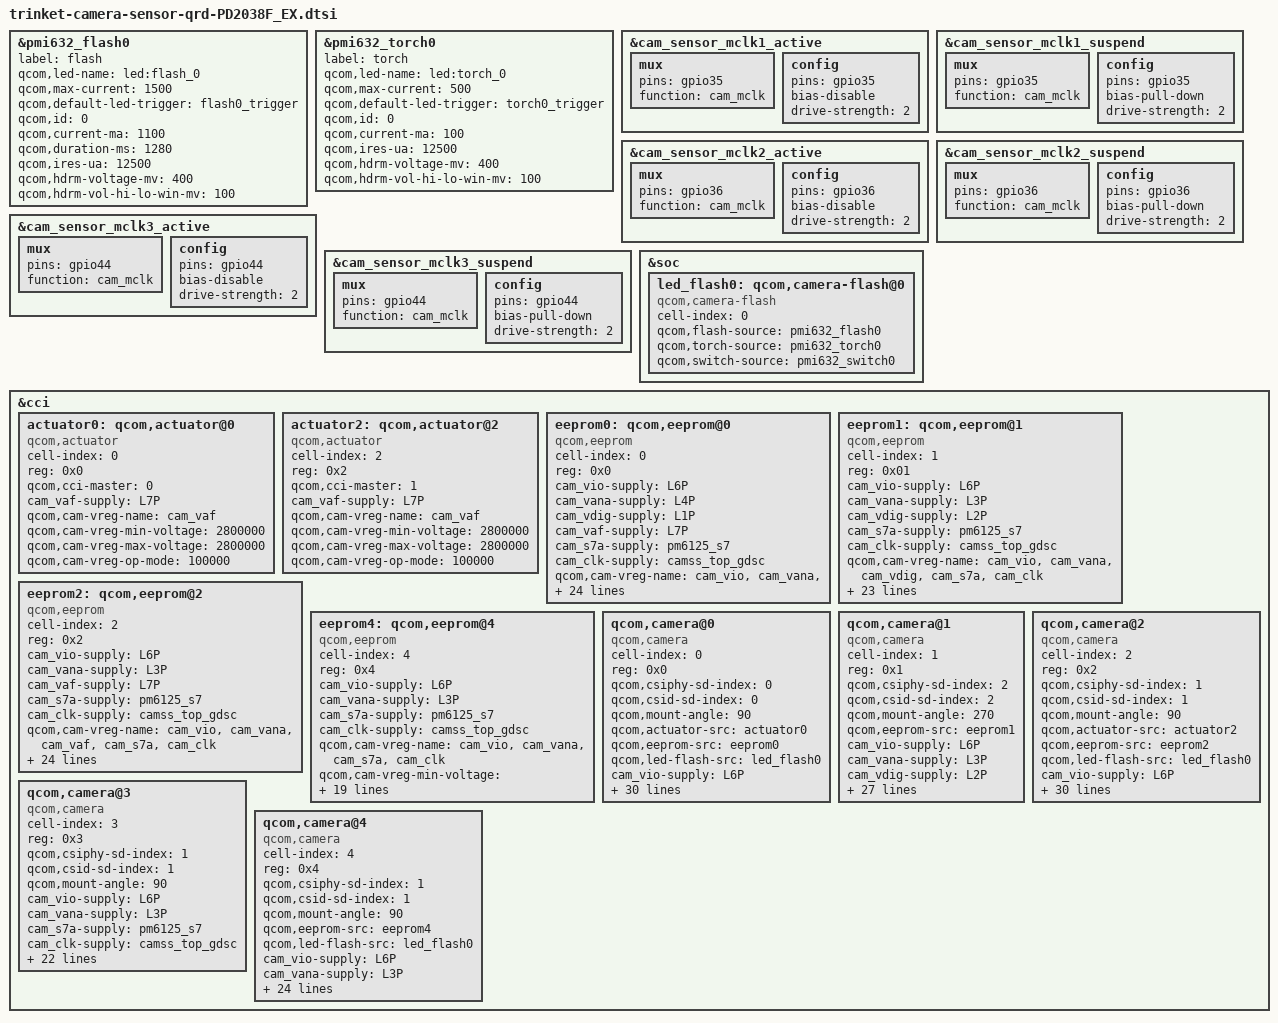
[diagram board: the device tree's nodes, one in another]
/*
 * Copyright (c) 2019, The Linux Foundation. All rights reserved.
 *
 * This program is free software; you can redistribute it and/or modify
 * it under the terms of the GNU General Public License version 2 and
 * only version 2 as published by the Free Software Foundation.
 *
 * This program is distributed in the hope that it will be useful,
 * but WITHOUT ANY WARRANTY; without even the implied warranty of
 * MERCHANTABILITY or FITNESS FOR A PARTICULAR PURPOSE.  See the
 * GNU General Public License for more details.
 */

&pmi632_flash0 {
	label = "flash";
	qcom,led-name = "led:flash_0";
	qcom,max-current = <1500>;
	qcom,default-led-trigger = "flash0_trigger";
	qcom,id = <0>;
	qcom,current-ma = <1100>;
	qcom,duration-ms = <1280>;
	qcom,ires-ua = <12500>;
	qcom,hdrm-voltage-mv = <400>;
	qcom,hdrm-vol-hi-lo-win-mv = <100>;
};

&pmi632_torch0 {
	label = "torch";
	qcom,led-name = "led:torch_0";
	qcom,max-current = <500>;
	qcom,default-led-trigger = "torch0_trigger";
	qcom,id = <0>;
	qcom,current-ma = <100>;
	qcom,ires-ua = <12500>;
	qcom,hdrm-voltage-mv = <400>;
	qcom,hdrm-vol-hi-lo-win-mv = <100>;
};

&cam_sensor_mclk1_active {
	/* MCLK2 */
	mux {
		pins = "gpio35";
		function = "cam_mclk";
	};

	config {
		pins = "gpio35";
		bias-disable; /* No PULL */
		drive-strength = <2>; /* 2 MA */
	};
};

&cam_sensor_mclk1_suspend {
	/* MCLK2 */
	mux {
		pins = "gpio35";
		function = "cam_mclk";
	};

	config {
		pins = "gpio35";
		bias-pull-down; /* PULL DOWN */
		drive-strength = <2>; /* 2 MA */
	};
};

&cam_sensor_mclk2_active {
	/* MCLK2 */
	mux {
		pins = "gpio36";
		function = "cam_mclk";
	};

	config {
		pins = "gpio36";
		bias-disable; /* No PULL */
		drive-strength = <2>; /* 2 MA */
	};
};

&cam_sensor_mclk2_suspend {
	/* MCLK2 */
	mux {
		pins = "gpio36";
		function = "cam_mclk";
	};

	config {
		pins = "gpio36";
		bias-pull-down; /* PULL DOWN */
		drive-strength = <2>; /* 2 MA */
	};
};

&cam_sensor_mclk3_active {
	/* MCLK3 */
	mux {
		pins = "gpio44";
		function = "cam_mclk";
	};

	config {
		pins = "gpio44";
		bias-disable; /* No PULL */
		drive-strength = <2>; /* 2 MA */
	};
};

&cam_sensor_mclk3_suspend {
	/* MCLK2 */
	mux {
		pins = "gpio44";
		function = "cam_mclk";
	};

	config {
		pins = "gpio44";
		bias-pull-down; /* PULL DOWN */
		drive-strength = <2>; /* 2 MA */
	};
};

&soc {
	led_flash0: qcom,camera-flash@0 {
		cell-index = <0>;
		compatible = "qcom,camera-flash";
		qcom,flash-source = <&pmi632_flash0>;
		qcom,torch-source = <&pmi632_torch0>;
		qcom,switch-source = <&pmi632_switch0>;
		status = "ok";
	};
};

&cci {
	actuator0: qcom,actuator@0 {
		cell-index = <0>;
		reg = <0x0>;
		compatible = "qcom,actuator";
		qcom,cci-master = <0>;
		cam_vaf-supply = <&L7P>;
		qcom,cam-vreg-name = "cam_vaf";
		qcom,cam-vreg-min-voltage = <2800000>;
		qcom,cam-vreg-max-voltage = <2800000>;
		qcom,cam-vreg-op-mode = <100000>;
	};

	actuator2: qcom,actuator@2 {
		cell-index = <2>;
		reg = <0x2>;
		compatible = "qcom,actuator";
		qcom,cci-master = <1>;
		cam_vaf-supply = <&L7P>;
		qcom,cam-vreg-name = "cam_vaf";
		qcom,cam-vreg-min-voltage = <2800000>;
		qcom,cam-vreg-max-voltage = <2800000>;
		qcom,cam-vreg-op-mode = <100000>;
	};

	eeprom0: qcom,eeprom@0 {
		cell-index = <0>;
		compatible = "qcom,eeprom";
		reg = <0x0>;
		cam_vio-supply = <&L6P>;
		cam_vana-supply = <&L4P>;
		cam_vdig-supply = <&L1P>;
		cam_vaf-supply = <&L7P>;
		cam_s7a-supply = <&pm6125_s7>;
		cam_clk-supply = <&camss_top_gdsc>;
		qcom,cam-vreg-name = "cam_vio", "cam_vana", "cam_vdig", "cam_vaf", "cam_s7a",  "cam_clk";
		qcom,cam-vreg-min-voltage = <1800000 2800000 1100000 2800000 2040000 0>;
		qcom,cam-vreg-max-voltage = <1800000 2800000 1100000 2800000 2040000 0>;
		qcom,cam-vreg-op-mode = <100000 100000 100000 100000 0 0>;
		qcom,gpio-no-mux = <0>;
		pinctrl-names = "cam_default", "cam_suspend";
		pinctrl-0 = <&cam_sensor_mclk1_active
				&cam_sensor_rear_active>;
		pinctrl-1 = <&cam_sensor_mclk1_suspend
				&cam_sensor_rear_suspend>;
		gpios = <&tlmm 35 0>, <&tlmm 48 0>;
		qcom,gpio-reset = <1>;
		qcom,gpio-req-tbl-num = <0 1>;
		qcom,gpio-req-tbl-flags = <1 0>;
		qcom,gpio-req-tbl-label = "CAMIF_MCLK0", "CAM_RESET0";
		qcom,sensor-position = <0>;
		qcom,sensor-mode = <0>;
		qcom,cci-master = <0>;
		status = "ok";
		clocks = <&clock_gcc GCC_CAMSS_MCLK1_CLK_SRC>,
				<&clock_gcc GCC_CAMSS_MCLK1_CLK>;
		clock-names = "cam_src_clk", "cam_clk";
		qcom,clock-rates = <24000000 0>;
	};

	eeprom1: qcom,eeprom@1 {
		cell-index = <1>;
		reg = <0x01>;
		compatible = "qcom,eeprom";
		cam_vio-supply = <&L6P>;
		cam_vana-supply = <&L3P>;
		cam_vdig-supply = <&L2P>;
		cam_s7a-supply = <&pm6125_s7>;
		cam_clk-supply = <&camss_top_gdsc>;
		qcom,cam-vreg-name = "cam_vio", "cam_vana", "cam_vdig", "cam_s7a", "cam_clk";
		qcom,cam-vreg-min-voltage = <1800000 2800000 1140000 2040000 0>;
		qcom,cam-vreg-max-voltage = <1800000 2800000 1140000 2040000 0>;
		qcom,cam-vreg-op-mode = <100000 100000 100000 0 0>;
		qcom,gpio-no-mux = <0>;
		pinctrl-names = "cam_default", "cam_suspend";
		pinctrl-0 = <&cam_sensor_mclk0_active
				 &cam_sensor_front_active>;
		pinctrl-1 = <&cam_sensor_mclk0_suspend
				 &cam_sensor_front_suspend>;
		gpios = <&tlmm 34 0>, <&tlmm 42 0>;
		qcom,gpio-reset = <1>;
		qcom,gpio-req-tbl-num = <0 1>;
		qcom,gpio-req-tbl-flags = <1 0>;
		qcom,gpio-req-tbl-label = "CAMIF_MCLK1", "CAM_RESET1";
		qcom,sensor-position = <1>;
		qcom,sensor-mode = <1>;
		qcom,cci-master = <0>;
		status = "ok";
		clocks = <&clock_gcc GCC_CAMSS_MCLK0_CLK_SRC>,
			<&clock_gcc GCC_CAMSS_MCLK0_CLK>;
		clock-names = "cam_src_clk", "cam_clk";
		qcom,clock-rates = <24000000 0>;
	};

	eeprom2: qcom,eeprom@2 {
		cell-index = <2>;
		reg = <0x2>;
		compatible = "qcom,eeprom";
		cam_vio-supply = <&L6P>;
		cam_vana-supply = <&L3P>;
		cam_vaf-supply = <&L7P>;
		cam_s7a-supply = <&pm6125_s7>;
		cam_clk-supply = <&camss_top_gdsc>;
		qcom,cam-vreg-name = "cam_vio", "cam_vana", "cam_vaf", "cam_s7a", "cam_clk";
		qcom,cam-vreg-min-voltage = <1800000 2800000 2800000 2040000 0>;
		qcom,cam-vreg-max-voltage = <1800000 2800000 2800000 2040000 0>;
		qcom,cam-vreg-op-mode = <100000 100000 100000 0 0>;
		qcom,gpio-no-mux = <0>;
		pinctrl-names = "cam_default", "cam_suspend";
		pinctrl-0 = <&cam_sensor_mclk2_active
				&cam_sensor_rear3_active>;
		pinctrl-1 = <&cam_sensor_mclk2_suspend
				&cam_sensor_rear3_suspend>;
		gpios = <&tlmm 36 0>, <&tlmm 20 0>, <&tlmm 41 0>;
		qcom,gpio-vdig = <1>;
		qcom,gpio-reset = <2>;
		qcom,gpio-req-tbl-num = <0 1 2>;
		qcom,gpio-req-tbl-flags = <1 0 0>;
		qcom,gpio-req-tbl-label = "CAMIF_MCLK2", "CAM_DVDD2", "CAM_RESET2";
		qcom,sensor-position = <0>;
		qcom,sensor-mode = <0>;
		qcom,cci-master = <1>;
		status = "ok";
		clocks = <&clock_gcc GCC_CAMSS_MCLK2_CLK_SRC>,
				<&clock_gcc GCC_CAMSS_MCLK2_CLK>;
		clock-names = "cam_src_clk", "cam_clk";
		qcom,clock-rates = <24000000 0>;
	};

	eeprom4: qcom,eeprom@4 {
		cell-index = <4>;
		reg = <0x4>;
		compatible = "qcom,eeprom";
		cam_vio-supply = <&L6P>;
		cam_vana-supply = <&L3P>;
		cam_s7a-supply = <&pm6125_s7>;
		cam_clk-supply = <&camss_top_gdsc>;
		qcom,cam-vreg-name = "cam_vio", "cam_vana", "cam_s7a", "cam_clk";
		qcom,cam-vreg-min-voltage = <1800000 2800000 2040000 0>;
		qcom,cam-vreg-max-voltage = <1800000 2800000 2040000 0>;
		qcom,cam-vreg-op-mode = <100000 100000 0 0>;
		qcom,gpio-no-mux = <0>;
		pinctrl-names = "cam_default", "cam_suspend";
		pinctrl-0 = <&cam_sensor_mclk2_active>;
		pinctrl-1 = <&cam_sensor_mclk2_suspend>;
		gpios = <&tlmm 36 0>, <&tlmm 41 0>;
		qcom,gpio-reset = <1>;
		qcom,gpio-req-tbl-num = <0 1>;
		qcom,gpio-req-tbl-flags = <1 0>;
		qcom,gpio-req-tbl-label = "CAMIF_MCLK2", "CAM_RESET2";
		qcom,sensor-position = <0>;
		qcom,sensor-mode = <0>;
		qcom,cci-master = <1>;
		status = "ok";
		clocks = <&clock_gcc GCC_CAMSS_MCLK2_CLK_SRC>,
				<&clock_gcc GCC_CAMSS_MCLK2_CLK>;
		clock-names = "cam_src_clk", "cam_clk";
		qcom,clock-rates = <24000000 0>;
	};

	/*Back camera 48M GM1ST*/
	qcom,camera@0 {
		cell-index = <0>;
		compatible = "qcom,camera";
		reg = <0x0>;
		qcom,csiphy-sd-index = <0>;
		qcom,csid-sd-index = <0>;
		qcom,mount-angle = <90>;
		qcom,actuator-src = <&actuator0>;
		qcom,eeprom-src = <&eeprom0>;
		qcom,led-flash-src = <&led_flash0>;
		cam_vio-supply = <&L6P>;
		cam_vana-supply = <&L4P>;
		cam_vdig-supply = <&L1P>;
		cam_vaf-supply = <&L7P>;
		cam_s7a-supply = <&pm6125_s7>;
		cam_clk-supply = <&camss_top_gdsc>;
		qcom,cam-vreg-name = "cam_vio", "cam_vana", "cam_vdig", "cam_vaf", "cam_s7a", "cam_clk";
		qcom,cam-vreg-min-voltage = <1800000 2800000 1100000 2800000 2040000 0>;
		qcom,cam-vreg-max-voltage = <1800000 2800000 1100000 2800000 2040000 0>;
		qcom,cam-vreg-op-mode = <100000 100000 100000 100000 0 0>;
		qcom,gpio-no-mux = <0>;
		pinctrl-names = "cam_default", "cam_suspend";
		pinctrl-0 = <&cam_sensor_mclk1_active
				&cam_sensor_rear_active>;
		pinctrl-1 = <&cam_sensor_mclk1_suspend
				&cam_sensor_rear_suspend>;
		gpios = <&tlmm 35 0>, <&tlmm 48 0>;
		qcom,gpio-reset = <1>;
		qcom,gpio-req-tbl-num = <0 1>;
		qcom,gpio-req-tbl-flags = <1 0>;
		qcom,gpio-req-tbl-label = "CAMIF_MCLK0", "CAM_RESET0";
		qcom,sensor-position = <0>;
		qcom,sensor-mode = <0>;
		qcom,cci-master = <0>;
		status = "ok";
		clocks = <&clock_gcc GCC_CAMSS_MCLK1_CLK_SRC>,
				<&clock_gcc GCC_CAMSS_MCLK1_CLK>;
		clock-names = "cam_src_clk", "cam_clk";
		qcom,clock-rates = <24000000 0>;
	};

	/*Front camera 16M s5k3p9sp ov32a10*/
	qcom,camera@1 {
		cell-index = <1>;
		compatible = "qcom,camera";
		reg = <0x1>;
		qcom,csiphy-sd-index = <2>;
		qcom,csid-sd-index = <2>;
		qcom,mount-angle = <270>;
		qcom,eeprom-src = <&eeprom1>;
		cam_vio-supply = <&L6P>;
		cam_vana-supply = <&L3P>;
		cam_vdig-supply = <&L2P>;
		cam_s7a-supply = <&pm6125_s7>;
		cam_clk-supply = <&camss_top_gdsc>;
		qcom,cam-vreg-name = "cam_vio", "cam_vana", "cam_vdig", "cam_s7a", "cam_clk";
		qcom,cam-vreg-min-voltage = <1800000 2800000 1140000 2040000 0>;
		qcom,cam-vreg-max-voltage = <1800000 2800000 1140000 2040000 0>;
		qcom,cam-vreg-op-mode = <100000 100000 100000 0 0>;
		qcom,gpio-no-mux = <0>;
		pinctrl-names = "cam_default", "cam_suspend";
		pinctrl-0 = <&cam_sensor_mclk0_active
				 &cam_sensor_front_active>;
		pinctrl-1 = <&cam_sensor_mclk0_suspend
				 &cam_sensor_front_suspend>;
		gpios = <&tlmm 34 0>, <&tlmm 42 0>;
		qcom,gpio-reset = <1>;
		qcom,gpio-req-tbl-num = <0 1>;
		qcom,gpio-req-tbl-flags = <1 0>;
		qcom,gpio-req-tbl-label = "CAMIF_MCLK1", "CAM_RESET1";
		qcom,sensor-position = <1>;
		qcom,sensor-mode = <1>;
		qcom,cci-master = <0>;
		status = "ok";
		clocks = <&clock_gcc GCC_CAMSS_MCLK0_CLK_SRC>,
			<&clock_gcc GCC_CAMSS_MCLK0_CLK>;
		clock-names = "cam_src_clk", "cam_clk";
		qcom,clock-rates = <19200000 0>;
	};

	/*Back wide camera 8M HI846*/
	qcom,camera@2 {
		cell-index = <2>;
		compatible = "qcom,camera";
		reg = <0x2>;
		qcom,csiphy-sd-index = <1>;
		qcom,csid-sd-index = <1>;
		qcom,mount-angle = <90>;
		qcom,actuator-src = <&actuator2>;
		qcom,eeprom-src = <&eeprom2>;
		qcom,led-flash-src = <&led_flash0>;
		cam_vio-supply = <&L6P>;
		cam_vana-supply = <&L3P>;
		cam_vaf-supply = <&L7P>;
		cam_s7a-supply = <&pm6125_s7>;
		cam_clk-supply = <&camss_top_gdsc>;
		qcom,cam-vreg-name = "cam_vio", "cam_vana", "cam_vaf", "cam_s7a", "cam_clk";
		qcom,cam-vreg-min-voltage = <1800000 2800000 2800000 2040000 0>;
		qcom,cam-vreg-max-voltage = <1800000 2800000 2800000 2040000 0>;
		qcom,cam-vreg-op-mode = <100000 100000 100000 0 0>;
		qcom,gpio-no-mux = <0>;
		pinctrl-names = "cam_default", "cam_suspend";
		pinctrl-0 = <&cam_sensor_mclk2_active
				&cam_sensor_rear3_active>;
		pinctrl-1 = <&cam_sensor_mclk2_suspend
				&cam_sensor_rear3_suspend>;
		gpios = <&tlmm 36 0>, <&tlmm 20 0>, <&tlmm 41 0>;
		qcom,gpio-vdig = <1>;
		qcom,gpio-reset = <2>;
		qcom,gpio-req-tbl-num = <0 1 2>;
		qcom,gpio-req-tbl-flags = <1 0 0>;
		qcom,gpio-req-tbl-label = "CAMIF_MCLK2", "CAM_DVDD2", "CAM_RESET2";
		qcom,sensor-position = <0>;
		qcom,sensor-mode = <0>;
		qcom,cci-master = <1>;
		status = "ok";
		clocks = <&clock_gcc GCC_CAMSS_MCLK2_CLK_SRC>,
				<&clock_gcc GCC_CAMSS_MCLK2_CLK>;
		clock-names = "cam_src_clk", "cam_clk";
		qcom,clock-rates = <24000000 0>;
	};

	/*Back aux bokeh camera 2M gc2375*/
	qcom,camera@3 {
		cell-index = <3>;
		compatible = "qcom,camera";
		reg = <0x3>;
		qcom,csiphy-sd-index = <1>;
		qcom,csid-sd-index = <1>;
		qcom,mount-angle = <90>;
		cam_vio-supply = <&L6P>;
		cam_vana-supply = <&L3P>;
		cam_s7a-supply = <&pm6125_s7>;
		cam_clk-supply = <&camss_top_gdsc>;
		qcom,cam-vreg-name = "cam_vio", "cam_vana", "cam_s7a", "cam_clk";
		qcom,cam-vreg-min-voltage = <1800000 2800000 2040000 0>;
		qcom,cam-vreg-max-voltage = <1800000 2800000 2040000 0>;
		qcom,cam-vreg-op-mode = <100000 100000 0 0>;
		qcom,gpio-no-mux = <0>;
		pinctrl-names = "cam_default", "cam_suspend";
		pinctrl-0 = <&cam_sensor_mclk3_active>;
		pinctrl-1 = <&cam_sensor_mclk3_suspend>;
		gpios = <&tlmm 44 0>, <&tlmm 52 0>;
		qcom,gpio-reset = <1>;
		qcom,gpio-req-tbl-num = <0 1>;
		qcom,gpio-req-tbl-flags = <1 0>;
		qcom,gpio-req-tbl-label = "CAMIF_MCLK3", "CAM_RESET3";
		qcom,sensor-position = <0x100>;
		qcom,sensor-mode = <0>;
		qcom,cci-master = <1>;
		status = "ok";
		clocks = <&clock_gcc GCC_CAMSS_MCLK3_CLK_SRC>,
			<&clock_gcc GCC_CAMSS_MCLK3_CLK>;
		clock-names = "cam_src_clk", "cam_clk";
		qcom,clock-rates = <24000000 0>;
	};
	/*Back microspur camera 2M hi259*/
	qcom,camera@4 {
		cell-index = <4>;
		compatible = "qcom,camera";
		reg = <0x4>;
		qcom,csiphy-sd-index = <1>;
		qcom,csid-sd-index = <1>;
		qcom,mount-angle = <90>;
		qcom,eeprom-src = <&eeprom4>;
		qcom,led-flash-src = <&led_flash0>;
		cam_vio-supply = <&L6P>;
		cam_vana-supply = <&L3P>;
		cam_s7a-supply = <&pm6125_s7>;
		cam_clk-supply = <&camss_top_gdsc>;
		qcom,cam-vreg-name = "cam_vio", "cam_vana", "cam_s7a", "cam_clk";
		qcom,cam-vreg-min-voltage = <1800000 2800000 2040000 0>;
		qcom,cam-vreg-max-voltage = <1800000 2800000 2040000 0>;
		qcom,cam-vreg-op-mode = <100000 100000 0 0>;
		qcom,gpio-no-mux = <0>;
		pinctrl-names = "cam_default", "cam_suspend";
		pinctrl-0 = <&cam_sensor_mclk2_active>;
		pinctrl-1 = <&cam_sensor_mclk2_suspend>;
		gpios = <&tlmm 36 0>, <&tlmm 41 0>;
		qcom,gpio-reset = <1>;
		qcom,gpio-req-tbl-num = <0 1>;
		qcom,gpio-req-tbl-flags = <1 2>;
		qcom,gpio-req-tbl-label = "CAMIF_MCLK2", "CAM_RESET2";
		qcom,sensor-position = <0>;
		qcom,sensor-mode = <0>;
		qcom,cci-master = <1>;
		status = "ok";
		clocks = <&clock_gcc GCC_CAMSS_MCLK2_CLK_SRC>,
			<&clock_gcc GCC_CAMSS_MCLK2_CLK>;
		clock-names = "cam_src_clk", "cam_clk";
		qcom,clock-rates = <24000000 0>;
	};
};
